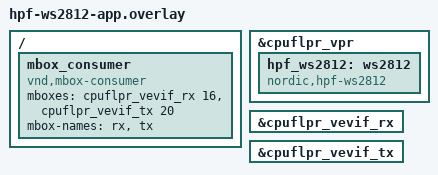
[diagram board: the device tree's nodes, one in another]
/* Copyright (c) 2024 Nordic Semiconductor ASA
 *
 * SPDX-License-Identifier: LicenseRef-Nordic-5-Clause
 */

/ {
	/* MBOX consumer configuration for HPF WS2812 communication */
	mbox_consumer: mbox_consumer {
		compatible = "vnd,mbox-consumer";
		mboxes = <&cpuflpr_vevif_rx 16>, <&cpuflpr_vevif_tx 20>;
		mbox-names = "rx", "tx";
	};

	/* Direct MBOX data transfer - no shared SRAM needed */
};

&cpuflpr_vpr {
	status = "okay";

	hpf_ws2812: ws2812 {
		compatible = "nordic,hpf-ws2812";
		status = "okay";
	};
};

/* Enable MBOX communication with ARM core */
&cpuflpr_vevif_rx {
	status = "okay";
};

&cpuflpr_vevif_tx {
	status = "okay";
};
